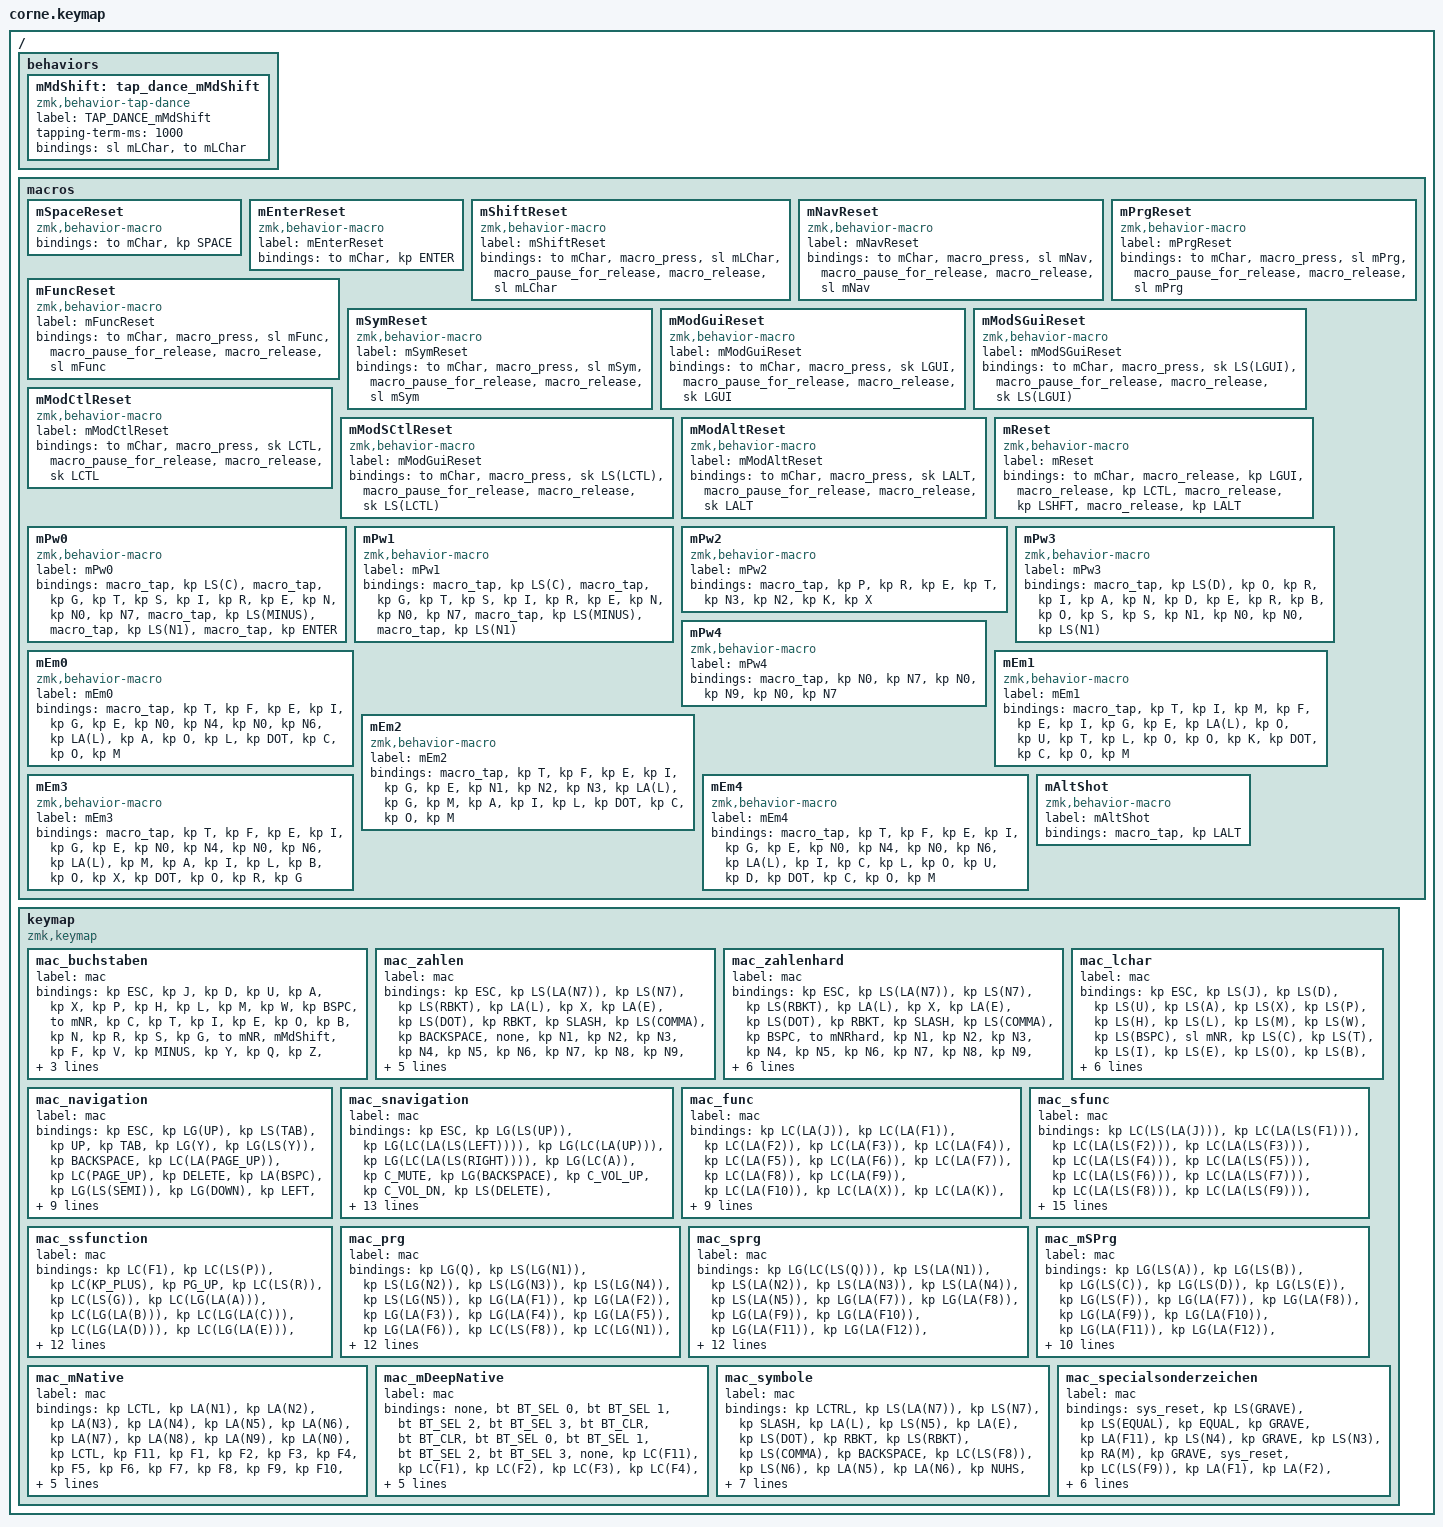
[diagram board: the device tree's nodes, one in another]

#include <behaviors.dtsi>
#include <dt-bindings/zmk/keys.h>
#include <dt-bindings/zmk/bt.h>


// ZMK Big



// ------- MAC -------------------

#define mChar 0
#define mNR 1
#define mNRhard 2
#define mLChar 3

#define mNav 4
#define mSNav 5

#define mFunc 6
#define mDFunc 7
#define mSFunc 8

#define mPrg 9
#define mDPrg 10
#define mSPrg 11

#define mNative 12
#define mDeepNative 13

#define mSym 14
#define mSSym 15





/ {

    behaviors 
	{

		//Tab Dance Shift
		mMdShift: tap_dance_mMdShift 
		{
            compatible = "zmk,behavior-tap-dance";
            label = "TAP_DANCE_mMdShift";
            #binding-cells = <0>;
            tapping-term-ms = <1000>;
            bindings = <&sl mLChar>, <&to mLChar>;
        };
    };

	


	macros 
	{

		//Reset Keys
        mSpaceReset: mSpaceReset 
		{
            compatible = "zmk,behavior-macro";
            #binding-cells = <0>;
            bindings
                = <&to mChar>
                , <&kp SPACE>
                ;
    	};
		mEnterReset: mEnterReset 
		{
            label = "mEnterReset";
            compatible = "zmk,behavior-macro";
            #binding-cells = <0>;
            bindings
                = <&to mChar>
                , <&kp ENTER>
                ;
    	};
		mShiftReset: mShiftReset
		{
            label = "mShiftReset";
            compatible = "zmk,behavior-macro";
            #binding-cells = <0>;
            bindings
                = <&to mChar>
                , <&macro_press &sl mLChar>
    			, <&macro_pause_for_release>
				, <&macro_release &sl mLChar>
                ;
    	};



		// Reset Stickys


				
		mNavReset: mNavReset 
		{
            label = "mNavReset";
            compatible = "zmk,behavior-macro";
            #binding-cells = <0>;
            bindings
                = <&to mChar>
                , <&macro_press &sl mNav>
    			, <&macro_pause_for_release>
				, <&macro_release &sl mNav>
                ;
    	};

		mPrgReset: mPrgReset 
		{
            label = "mPrgReset";
            compatible = "zmk,behavior-macro";
            #binding-cells = <0>;
            bindings
                = <&to mChar>
                , <&macro_press &sl mPrg>
    			, <&macro_pause_for_release>
				, <&macro_release &sl mPrg>
                ;
    	};

		mFuncReset: mFuncReset
		{
            label = "mFuncReset";
            compatible = "zmk,behavior-macro";
            #binding-cells = <0>;
            bindings
                = <&to mChar>
                , <&macro_press &sl mFunc>
    			, <&macro_pause_for_release>
				, <&macro_release &sl mFunc>
                ;
    	};

		mSymReset: mSymReset
		{
            label = "mSymReset";
            compatible = "zmk,behavior-macro";
            #binding-cells = <0>;
            bindings
                = <&to mChar>
                , <&macro_press &sl mSym>
    			, <&macro_pause_for_release>
				, <&macro_release &sl mSym>
                ;
    	};






		// Special Layer Reset

		mModGuiReset: mModGuiReset
		{
            label = "mModGuiReset";
            compatible = "zmk,behavior-macro";
            #binding-cells = <0>;
            bindings
                = <&to mChar>
                , <&macro_press &sk LGUI>
    			, <&macro_pause_for_release>
				, <&macro_release &sk LGUI>
                ;
    	};

		mModSGuiReset: mModSGuiReset
		{
            label = "mModSGuiReset";
            compatible = "zmk,behavior-macro";
            #binding-cells = <0>;
            bindings
                = <&to mChar>
                , <&macro_press &sk LS(LGUI)>
    			, <&macro_pause_for_release>
				, <&macro_release &sk LS(LGUI)>
                ;
    	};

		mModCtlReset: mModCtlReset
		{
            label = "mModCtlReset";
            compatible = "zmk,behavior-macro";
            #binding-cells = <0>;
            bindings
                = <&to mChar>
                , <&macro_press &sk LCTL>
    			, <&macro_pause_for_release>
				, <&macro_release &sk LCTL>
                ;
    	};

		mModSCtlReset: mModSCtlReset
		{
            label = "mModGuiReset";
            compatible = "zmk,behavior-macro";
            #binding-cells = <0>;
            bindings
                = <&to mChar>
                , <&macro_press &sk LS(LCTL)>
    			, <&macro_pause_for_release>
				, <&macro_release &sk LS(LCTL)>
                ;
    	};

		mModAltReset: mModAltReset
		{
            label = "mModAltReset";
            compatible = "zmk,behavior-macro";
            #binding-cells = <0>;
            bindings
                = <&to mChar>
                , <&macro_press &sk LALT>
    			, <&macro_pause_for_release>
				, <&macro_release &sk LALT>
                ;
    	};






		// Reset 

		mReset: mReset {
            label = "mReset";
            compatible = "zmk,behavior-macro";
            #binding-cells = <0>;
            bindings
				= <&to mChar>
				, <&macro_release  &kp LGUI>
				, <&macro_release  &kp LCTL>
				, <&macro_release  &kp LSHFT>
				, <&macro_release  &kp LALT>
                ; 
    	};
		






		// Pass Wort Macros

		mPw0: mPw0 {
            label = "mPw0";
            compatible = "zmk,behavior-macro";
            #binding-cells = <0>;
            bindings
				= < &macro_tap &kp LS(C)>
				, < &macro_tap &kp G &kp T &kp S &kp I &kp R &kp E &kp N &kp N0 &kp N7 >
				, < &macro_tap &kp LS(MINUS)>
				, < &macro_tap &kp LS(N1)>
				, < &macro_tap &kp ENTER>
                ; 
    	};
		
		mPw1: mPw1 {
            label = "mPw1";
            compatible = "zmk,behavior-macro";
            #binding-cells = <0>;
            bindings
				= < &macro_tap &kp LS(C)>
				, < &macro_tap &kp G &kp T &kp S &kp I &kp R &kp E &kp N &kp N0 &kp N7 >
				, < &macro_tap &kp LS(MINUS)>
				, < &macro_tap &kp LS(N1)>
                ; 
    	};


		mPw2: mPw2 {
            label = "mPw2";
            compatible = "zmk,behavior-macro";
            #binding-cells = <0>;
            bindings
				= <&macro_tap &kp P &kp R &kp E &kp T &kp N3 &kp N2 &kp K &kp X >
                ; 
    	};


		mPw3: mPw3 {
            label = "mPw3";
            compatible = "zmk,behavior-macro";
            #binding-cells = <0>;
            bindings
				= <&macro_tap &kp LS(D) &kp O &kp R &kp I &kp A &kp N &kp D &kp E &kp R &kp B &kp O &kp S &kp S &kp N1 &kp N0 &kp N0 &kp LS(N1) >
                ; 
    	};

		mPw4: mPw4 {
            label = "mPw4";
            compatible = "zmk,behavior-macro";
            #binding-cells = <0>;
            bindings
				= <&macro_tap &kp N0  &kp N7  &kp N0  &kp N9  &kp N0  &kp N7>
                ; 
    	};

		

		// Email

		mEm0: mEm0 {
            label = "mEm0";
            compatible = "zmk,behavior-macro";
            #binding-cells = <0>;
            bindings
				= < &macro_tap &kp T &kp F &kp E &kp I &kp G &kp E &kp N0 &kp N4 &kp N0  &kp N6  &kp LA(L)  &kp A  &kp O  &kp L  &kp DOT  &kp C  &kp O  &kp M>
                ; 
    	};

		mEm1: mEm1 {
            label = "mEm1";
            compatible = "zmk,behavior-macro";
            #binding-cells = <0>;
            bindings
				= < &macro_tap &kp T &kp I &kp M &kp F &kp E &kp I &kp G &kp E &kp LA(L)  &kp O  &kp U  &kp T  &kp L  &kp O &kp O &kp K  &kp DOT  &kp C  &kp O  &kp M>
                ; 
    	};

		mEm2: mEm2 {
            label = "mEm2";
            compatible = "zmk,behavior-macro";
            #binding-cells = <0>;
            bindings
				= < &macro_tap &kp T &kp F &kp E &kp I &kp G &kp E &kp N1 &kp N2  &kp N3 &kp LA(L)  &kp G  &kp M  &kp A  &kp I  &kp L  &kp DOT  &kp C  &kp O  &kp M>
                ; 
    	};

		mEm3: mEm3 {
            label = "mEm3";
            compatible = "zmk,behavior-macro";
            #binding-cells = <0>;
            bindings
				= < &macro_tap &kp T &kp F &kp E &kp I &kp G &kp E &kp N0 &kp N4 &kp N0  &kp N6  &kp LA(L)  &kp M  &kp A  &kp I  &kp L  &kp B  &kp O  &kp X  &kp DOT  &kp O  &kp R  &kp G>
                ; 
    	};

		mEm4: mEm4 {
            label = "mEm4";
            compatible = "zmk,behavior-macro";
            #binding-cells = <0>;
            bindings
				= < &macro_tap &kp T &kp F &kp E &kp I &kp G &kp E &kp N0 &kp N4 &kp N0  &kp N6  &kp LA(L)  &kp I  &kp C  &kp L  &kp O  &kp U  &kp D  &kp DOT  &kp C  &kp O  &kp M>
                ; 
    	};


		// Email

		mAltShot: mAltShot {
            label = "mAltShot";
            compatible = "zmk,behavior-macro";
            #binding-cells = <0>;
            bindings
				= < &macro_tap &kp LALT>
                ; 
    	};



	};





	keymap
	{	
		compatible = "zmk,keymap";


		// -----------------------------------------------------|
		// 							Buchstaben					|
		// -----------------------------------------------------|
	
		mac_buchstaben
		{
			label = "mac";

			bindings = <

				// ----------------------------------------

				&kp ESC
				&kp J 
				&kp D	 
				&kp U
				&kp A
				&kp X

				&kp P
				&kp H
				&kp L
				&kp M
				&kp W
				&kp BSPC

				// ----------------------------------------
	
				&to mNR
				&kp C
				&kp T
				&kp I
				&kp E
				&kp O

				&kp B
				&kp N
				&kp R
				&kp S
				&kp G
				&to mNR

				// ----------------------------------------
	
				&mMdShift
				&kp F
				&kp V
				&kp MINUS
				&kp Y
				&kp Q

				&kp Z
				&kp SEMI
				&kp LBKT
				&kp SQT
				&kp K
				&mMdShift

				// ----------------------------------------

				&sl mSym
				&kp SPACE
				&sl mFunc
				&sl mPrg 
				&sl mNav
				&sl mSym

				// ----------------------------------------
			>;
		};



		// -----------------------------------------------------|
		//						Zahlen 							|
		// -----------------------------------------------------|

		mac_zahlen
		{
			label = "mac";

			bindings = <

				// ----------------------------------------

				&kp ESC
				&kp LS(LA(N7))			// backlslash
				&kp LS(N7)				// /
				&kp LS(RBKT)			// *
				&kp LA(L)				// @
				&kp X
				
				&kp LA(E)				// €
				&kp LS(DOT)				// :
				&kp RBKT  				// +
				&kp SLASH 				// -
				&kp LS(COMMA)			// ;
				&kp BACKSPACE

				// ----------------------------------------

				&none
				&kp N1				
				&kp N2 
				&kp N3				
				&kp N4					
				&kp N5		

				&kp N6				
				&kp N7				
				&kp N8			
				&kp N9				
				&kp N0				
				&none

				// ----------------------------------------

				&mMdShift
				&kp LS(NUHS)			// '
				&kp NUBS				// Spitze
				&kp LS(NUBS)			// Spitze 
				&kp LS(N2)				// "
				&kp LS(SLASH)			// _

				&kp LS(N0)				// =
				&kp DOT					// .
				&kp COMMA				// ,
				&kp LA(N)				// ~
				&kp LA(N7)				// grader strich
				&mMdShift

				// ----------------------------------------
		
				&sl mSym
				&mSpaceReset 
				&mFuncReset
				&mPrgReset
				&mNavReset
				&sl mSym
			>;		
		};

		
		

		// -----------------------------------------------------|
		// 				 Zahlen Hard Lock						
		// -----------------------------------------------------|

		mac_zahlenhard
		{
			label = "mac";

			bindings = <

				// ----------------------------------------

				&kp ESC
				&kp LS(LA(N7))			// backlslash
				&kp LS(N7)				// /
				&kp LS(RBKT)			// *
				&kp LA(L)				// @
				&kp X
				
				&kp LA(E)				// €
				&kp LS(DOT)				// :
				&kp RBKT  				// +
				&kp SLASH 				// -
				&kp LS(COMMA)			// ;
				&kp BSPC

				// ----------------------------------------

				&to mNRhard
				&kp N1				
				&kp N2				
				&kp N3				
				&kp N4					
				&kp N5		

				&kp N6				
				&kp N7				
				&kp N8				
				&kp N9				
				&kp N0				
				&to mNRhard

				// ----------------------------------------

				&mMdShift
				&kp LS(NUHS)			// '
				&kp NUBS				// Spitze
				&kp LS(NUBS)			// Spitze 
				&kp LS(N2)				// "
				&kp LS(SLASH)			// _

				&kp LS(N0)				// =
				&kp DOT					// .
				&kp COMMA				// ,
				&kp LA(N)				// ~
				&kp LA(N7)				// grader strich
				&mMdShift

				// ----------------------------------------
		
				&sl mSym
				&kp SPACE
				&sl mFunc
				&sl mPrg
				&sl mNav
				&sl mSym
			>;		
		};




		// -----------------------------------------------------|
		// 							Buchstaben Lock				|
		// -----------------------------------------------------|
	
		mac_lchar
		{
			label = "mac";

			bindings = <

				// ----------------------------------------

				&kp ESC
				&kp LS(J) 
				&kp LS(D)	 
				&kp LS(U)
				&kp LS(A)
				&kp LS(X)

				&kp LS(P)
				&kp LS(H)
				&kp LS(L)
				&kp LS(M)
				&kp LS(W)
				&kp LS(BSPC) 

				// ----------------------------------------
	
				&sl mNR
				&kp LS(C)
				&kp LS(T)
				&kp LS(I)
				&kp LS(E)
				&kp LS(O)
			
				&kp LS(B)
				&kp LS(N)
				&kp LS(R)
				&kp LS(S)
				&kp LS(G)
				&sl mNR

				// ----------------------------------------

				&mMdShift
				&kp LS(F)
				&kp LS(V)
				&kp LS(MINUS)
				&kp LS(Y)
				&kp LS(Q)

				&kp LS(Z)
				&kp LS(SEMI)
				&kp LS(LBKT)
				&kp LS(SQT)
				&kp LS(K)
				&mMdShift

				// ----------------------------------------

				&sl mSym
				&mSpaceReset 
				&mFuncReset
				&mPrgReset
				&sl mNav
				&sl mSym

				// ----------------------------------------		
			>;
		};






		// -----------------------------------------------------|
		// 						Navigation						|
		// -----------------------------------------------------|

		mac_navigation
		{		
			label = "mac";

			bindings = <

				// ----------------------------------------

				&kp ESC
				&kp LG(UP)					
				&kp LS(TAB)
				&kp UP						
				&kp TAB
				&kp LG(Y)

				&kp LG(LS(Y))
				&kp BACKSPACE
				&kp LC(LA(PAGE_UP))
				&kp LC(PAGE_UP)
				&kp DELETE
				&kp LA(BSPC)					


				// ----------------------------------------

				&kp LG(LS(SEMI))
				&kp LG(DOWN)				// @End Sprung
				&kp LEFT 					// @Left
				&kp DOWN					// @Down
				&kp RIGHT 					// @Right
				&kp ENTER					
				
				&kp LC(LS(F10))				
				&kp LSHFT
				&kp LC(LA(PAGE_DOWN))
				&kp LC(PAGE_DOWN)
				&kp LCTL
				&kp LG(ENTER)
				
				// ----------------------------------------

				&kp LG(SEMI)
				&kp LG(LEFT)				// @Home 
				&kp LA(LEFT)				// @Wort Sprung
				&kp LA(RIGHT)				// @Wort Sprung
				&kp LG(RIGHT)				// @End  
				&kp LG(SQT)

				&kp LC(LA(LG(ENTER)))		// Altshot bzw Shortcat
				&kp LC(LA(F11))				
				&kp LC(LS(TAB))
				&kp LC(TAB)
				&kp LC(LA(F12))				
				&kp LALT

				// ----------------------------------------

				&sl mSym
				&to mNRhard
				&sl mFunc
				&sl mPrg
				&sl mSNav
				&sl mSym

				// ----------------------------------------							
			>;
		};


		// -----------------------------------------------------|
		//					Deep Navigation						|
		// -----------------------------------------------------|

		mac_snavigation
		{		
			label = "mac";

			bindings = <

				// ----------------------------------------

				&kp ESC 
				&kp LG(LS(UP))					
				&kp LG(LC(LA(LS(LEFT))))
				&kp LG(LC(LA(UP)))
				&kp LG(LC(LA(LS(RIGHT))))
				&kp LG(LC(A))		

				&kp C_MUTE
				&kp LG(BACKSPACE)
				&kp C_VOL_UP
				&kp C_VOL_DN
				&kp LS(DELETE)
				&kp LC(LS(BACKSPACE))

				// ----------------------------------------
		
				&kp LG(LS(SEMI))
				&kp LG(LS(DOWN))				// @End Sprung
				&kp LG(LC(LA(LEFT)))
				&kp LG(LC(LA(DOWN)))
				&kp LG(LC(LA(RIGHT)))
				&kp LG(LS(SQT))	

				&kp C_PLAY			
				&kp C_BRI_INC
				&kp C_PREV
				&kp C_NEXT
				&kp C_BRI_DEC
				&kp LCTL

				// ----------------------------------------

				&kp LG(LA(SEMI))
				&kp LG(LS(LEFT))				// @Home 
				&kp LA(LS(LEFT))				// @Wort Sprung
				&kp LA(LS(RIGHT))				// @Wort Sprung
				&kp LG(LS(RIGHT))				// @End  
				&kp LG(LA(SQT))
				
				&kp LG(LS(SEMI))
				&kp LC(LA(LS(F11)))
				&kp LC(LA(LEFT))
				&kp LC(LA(RIGHT))
				&kp LC(LA(LS(F12)))			
				&kp LG(LS(SQT))

				// ----------------------------------------
		
				&sl mSym
				&kp SPACE				
				&sl mFunc
				&sl mPrg
				&sl mNav
				&sl mSym

				// ----------------------------------------							
			>;
		};




				











		// -----------------------------------------------------|
		// Funktionen											|
		// -----------------------------------------------------|

		mac_func
		{
			label = "mac";

			bindings = <

				// ----------------------------------------
	
				&kp LC(LA(J))	
				&kp LC(LA(F1))	
				&kp LC(LA(F2))	
				&kp LC(LA(F3))	
				&kp LC(LA(F4))	
				&kp LC(LA(F5))	

				&kp LC(LA(F6))	
				&kp LC(LA(F7))	
				&kp LC(LA(F8))	
				&kp LC(LA(F9))	
				&kp LC(LA(F10))	
				&kp LC(LA(X))	
				
				// ----------------------------------------

				&kp LC(LA(K))	
				&kp LG(A)
				&kp LC(LA(A))	
				&kp LC(LA(B))	
				&kp LG(C)			
				&kp LG(X)

				&kp LC(LA(O))	
				&kp LG(V)
				&kp LC(LA(T))	
				&kp LC(LA(U))	
				&kp LC(LA(V))	
				&kp LC(LA(W))	

				// ----------------------------------------

				&kp LC(LA(I))	
				&kp LC(LA(S))
				&kp LC(LA(N))				
				&kp LC(LA(M))
				&kp LC(LA(R))	
				&kp LC(LA(G))

				&kp LC(LA(H))
				&kp LC(LA(F))	
				&kp LC(LA(D))	
				&kp LC(LA(C))	
				&kp LC(LA(E))
				&kp LC(LA(Y))	
				
				// ----------------------------------------

				&sl mSym
				&sl mSFunc
				&sl mDFunc					
				&sl mNative
				&mModCtlReset
				&sl mSym

				// ----------------------------------------
			>;
		};



		// -----------------------------------------------------|
		// 						Spezial Funktionen				|
		// -----------------------------------------------------|

		mac_sfunc
		{
			label = "mac";

			bindings = <

			// ----------------------------------------
	
				&kp LC(LS(LA(J)))	
				&kp LC(LA(LS(F1)))	
				&kp LC(LA(LS(F2)))	
				&kp LC(LA(LS(F3)))	
				&kp LC(LA(LS(F4)))
				&kp LC(LA(LS(F5)))

				&kp LC(LA(LS(F6)))	
				&kp LC(LA(LS(F7)))	
				&kp LC(LA(LS(F8)))	
				&kp LC(LA(LS(F9)))
				&kp LC(LA(LS(F10)))
				&kp LC(LS(LA(X)))	
				
				// ----------------------------------------

				&kp LC(LS(LA(K)))	
				&kp LC(LS(LA(P)))	
				&kp LC(LS(LA(A)))	
				&kp LC(LS(LA(B)))
				&kp LC(LS(LA(C)))			
				&kp LC(LS(LA(X)))	

				&kp LC(LS(LA(O)))
				&kp LC(LS(LA(V)))	
				&kp LC(LS(LA(T)))	
				&kp LC(LS(LA(U)))	
				&kp LC(LS(LA(L)))
				&kp LC(LS(LA(W)))	
					

				// ----------------------------------------

				&kp LC(LS(LA(I)))	
				&kp LC(LS(LA(S)))	
				&kp LC(LS(LA(N)))
				&kp LC(LS(LA(M)))
				&kp LC(LS(LA(R)))	
				&kp LC(LS(LA(G)))	

				&kp LC(LA(LS(H)))	
				&kp LC(LS(LA(F)))
				&kp LC(LS(LA(D)))
				&kp LC(LS(LA(C)))
				&kp LC(LS(LA(E)))
				&kp LC(LS(LA(Y)))	
				
				// ----------------------------------------

				&sl mSym	
				&mModGuiReset
				&sl mDFunc
				&sl mDeepNative
				&mModSCtlReset
				&sl mSym

				// ----------------------------------------       
			>;
		};







		// -----------------------------------------------------|
		// 				Super Special Function					|
		// -----------------------------------------------------|

		mac_ssfunction
		{
			label = "mac";

			bindings = <

			// ----------------------------------------

				&kp LC(F1)
				&kp LC(LS(P))
				&kp LC(KP_PLUS)
				&kp PG_UP
				&kp LC(LS(R))
				&kp LC(LS(G))

				&kp LC(LG(LA(A)))
				&kp LC(LG(LA(B)))
				&kp LC(LG(LA(C)))
				&kp LC(LG(LA(D)))
				&kp LC(LG(LA(E)))
				&kp LC(LG(LA(F)))

				// ----------------------------------------
		
				&kp LA(TAB)
				&kp LC(P)
				&kp LC(KP_MINUS)
				&kp PG_DN
				&kp LC(R)
				&kp LC(G)

				&kp LC(LG(LA(G)))
				&kp LC(LG(LA(I)))
				&kp LC(LG(LA(J)))
				&kp LC(LG(LA(K)))
				&kp LC(LG(LA(L)))
				&kp LC(LG(LA(M)))

				// ----------------------------------------

				&kp LC(LS(S))
				&kp LC(S)
				&kp LC(Y)
				&kp LC(LS(Y))
				&kp LC(LG(LA(W)))
				&kp LG(LS(S))

				&kp LC(LG(LA(N)))
				&kp LC(LG(LA(O)))
				&kp LC(LG(LA(P)))
				&kp LC(LG(LA(Q)))
				&kp LC(LG(LA(R)))
				&kp LC(LG(LA(S)))

				// ----------------------------------------
		
				&sl mSym	
				&kp SPACE
				&sl mFunc				
				&sl mSPrg
				&mModAltReset
				&sl mSym

				// ----------------------------------------
				
			>;
		};


		












		// -----------------------------------------------------|
		//  				Programme							|
		// -----------------------------------------------------|

		mac_prg
		{
			label = "mac";

			bindings = <

				// ----------------------------------------

				&kp LG(Q)
				&kp LS(LG(N1))			// 21 			
				&kp LS(LG(N2))			// 22
				&kp LS(LG(N3))			// 23
				&kp LS(LG(N4))			// 24
				&kp LS(LG(N5))			// 25
	
				&kp LG(LA(F1))			// 26
				&kp LG(LA(F2))			// 26
				&kp LG(LA(F3))			// 26
				&kp LG(LA(F4))			// 26
				&kp LG(LA(F5))			// 26
				&kp LG(LA(F6))			// 26

				// ----------------------------------------

				&kp LC(LS(F8))				// prg wechsel
				&kp LC(LG(N1))			
				&kp LC(LG(N2))		
				&kp LC(LG(N3))			
				&kp LC(LG(N4))			
				&kp LC(LG(N5))			

				&kp LG(LC(LA(F1)))
				&kp LG(LC(LA(F2)))
				&kp LG(LC(LA(F3)))
				&kp LG(LC(LA(F4)))
				&kp LG(LC(LA(F5)))
				&kp LG(LC(LA(F6)))

				// ----------------------------------------

				&kp LC(LS(F9))					// Prg Wechsel	
				&kp LC(LG(N6))				
				&kp LC(LG(N7))				
				&kp LC(LG(N8))				
				&kp LC(LG(N9))				
				&kp LC(LG(N0))			

				&kp LG(LC(LA(F7)))
				&kp LG(LC(LA(F8)))
				&kp LG(LC(LA(F9)))
				&kp LG(LC(LA(F10)))
				&kp LG(LC(LA(F11)))
				&kp LG(LC(LA(F12)))
		
				// ----------------------------------------

				&sl mSym
				&kp LG(LC(LA(X)))		
				&sl mNative
				&sl mDPrg					// deep						
				&sl mSPrg					// special
				&sl mSym

				// ----------------------------------------

			>;
		};
		


		// -----------------------------------------------------|
		// 		Spezial Prgramme								|
		// -----------------------------------------------------|


		mac_sprg
		{

			label = "mac";

			bindings = <

				// ----------------------------------------

				&kp LG(LC(LS(Q)))
				&kp LS(LA(N1))			// 21 			
				&kp LS(LA(N2))			// 22
				&kp LS(LA(N3))			// 23
				&kp LS(LA(N4))			// 24
				&kp LS(LA(N5))			// 25

				&kp LG(LA(F7))			// 
				&kp LG(LA(F8))			// 
				&kp LG(LA(F9))			// 
				&kp LG(LA(F10))			// 
				&kp LG(LA(F11))			// 
				&kp LG(LA(F12))			// 
				
				// ----------------------------------------

				&kp LG(LC(LS(M)))
				&kp LG(LC(LA(N1)))
				&kp LG(LC(LA(N2)))
				&kp LG(LC(LA(N3)))
				&kp LG(LC(LA(N4)))
				&kp LG(LC(LA(N5)))

				&kp LG(LS(F1))
				&kp LG(LS(F2))
				&kp LG(LS(F3))
				&kp LG(LS(F4))
				&kp LG(LS(F5))
				&kp LG(LS(F6))

				// ----------------------------------------

				&kp LG(LC(LS(N)))
				&kp LG(LC(LA(N6)))
				&kp LG(LC(LA(N7)))
				&kp LG(LC(LA(N8)))
				&kp LG(LC(LA(N9)))
				&kp LG(LC(LA(N0)))

				&kp LG(LS(F7))
				&kp LG(LS(F8))
				&kp LG(LS(F9))
				&kp LG(LS(F10))
				&kp LG(LS(F11))
				&kp LG(LS(F12))

				// ----------------------------------------

				&sl mSym
				&kp LG(LC(LA(Y)))			
				&sl mDeepNative
				&sl mDPrg
				&sl mSPrg				
				&sl mSym		

				// ----------------------------------------

			>;
		};





		// -----------------------------------------------------|
		// 		Super Special Program
		// -----------------------------------------------------|

		mac_mSPrg
		{
			label = "mac";

			bindings = <

				// ----------------------------------------

				&kp LG(LS(A))
				&kp LG(LS(B))
				&kp LG(LS(C))
				&kp LG(LS(D))
				&kp LG(LS(E))
				&kp LG(LS(F))

				&kp LG(LA(F7))			// 
				&kp LG(LA(F8))			// 
				&kp LG(LA(F9))			// 
				&kp LG(LA(F10))			// 
				&kp LG(LA(F11))			// 
				&kp LG(LA(F12))			// 


				// ----------------------------------------
		
				&kp LG(LS(G))
				&kp LG(LS(I))
				&kp LG(LS(J))
				&kp LG(LS(K))
				&kp LG(LS(L))
				&kp LG(LS(M))

				&kp LG(LS(F1))
				&kp LG(LS(F2))
				&kp LG(LS(F3))
				&kp LG(LS(F4))
				&kp LG(LS(F5))
				&kp LG(LS(F6))


				// ----------------------------------------

				&kp LG(LS(N))
				&kp LG(LS(O))
				&kp LG(LS(P))
				&kp LG(LS(Q))
				&kp LG(LS(R))
				&kp LG(LS(S))

				&kp LG(LS(F7))
				&kp LG(LS(F8))
				&kp LG(LS(F9))
				&kp LG(LS(F10))
				&kp LG(LS(F11))
				&kp LG(LS(F12))

				// ----------------------------------------
		
				&sl mSym
				&kp LG(LC(LA(Z)))		
				&sl mFunc
				&sl mPrg				
				&sl mNav
				&sl mSym

				// ----------------------------------------

				
			>;
		};

		






		// -----------------------------------------------------|
		// 					Nativ 								|
		// -----------------------------------------------------|

		mac_mNative
		{
			label = "mac";

			bindings = <

			// ----------------------------------------

				&kp LCTL
				&kp LA(N1)
				&kp LA(N2)
				&kp LA(N3)
				&kp LA(N4)
				&kp LA(N5)

				&kp LA(N6)
				&kp LA(N7)
				&kp LA(N8)
				&kp LA(N9)
				&kp LA(N0)
				&kp LCTL

				// ----------------------------------------
		
				&kp F11
				&kp F1
				&kp F2
				&kp F3
				&kp F4
				&kp F5

				&kp F6
				&kp F7
				&kp F8
				&kp F9
				&kp F10
				&kp F12
		

				// ----------------------------------------

				&kp LSHFT
				&kp LC(N1)
				&kp LC(N2)
				&kp LC(N3)
				&kp LC(N4)
				&kp LC(N5)

				&kp LC(N6)
				&kp LC(N7)
				&kp LC(N8)
				&kp LC(N9)
				&kp LC(N0)
				&kp LSHFT

				// ----------------------------------------
		
				&sl mSym					
				&kp SPACE
				&sl mFunc				
				&sl mPrg				
				&sl mNav
				&sl mSym

				// ----------------------------------------
				
			>;
		};


		
		// -----------------------------------------------------|
		// 				deep Native
		// -----------------------------------------------------|

		mac_mDeepNative
		{
			label = "mac";

			bindings = <

				// ----------------------------------------

				&none
				&bt BT_SEL 0
				&bt BT_SEL 1
				&bt BT_SEL 2
				&bt BT_SEL 3
				&bt BT_CLR

				&bt BT_CLR
				&bt BT_SEL 0
				&bt BT_SEL 1
				&bt BT_SEL 2
				&bt BT_SEL 3
				&none


				// ----------------------------------------
		
				&kp LC(F11)
				&kp LC(F1)
				&kp LC(F2)
				&kp LC(F3)
				&kp LC(F4)
				&kp LC(F5)

				&kp LC(F6)
				&kp LC(F7)
				&kp LC(F8)
				&kp LC(F9)
				&kp LC(F10)
				&kp LC(F12)


				// ----------------------------------------

				&none
				&none
				&none
				&none
				&none
				&none				

				&none
				&none
				&none
				&none
				&none
				&none


				// ----------------------------------------
		
				&sl mSym					
				&kp SPACE
				&sl mFunc				
				&sl mPrg				
				&sl mNav
				&sl mSym

				// ----------------------------------------

				
			>;
		};













		// -----------------------------------------------------|
		// 						Symoble							|
		// -----------------------------------------------------|

		mac_symbole
		{
			label = "mac";

			bindings = <

				// ----------------------------------------
				
				&kp LCTRL
				&kp LS(LA(N7))			// backlslash
				&kp LS(N7)				// /
				&kp SLASH 				// -
				&kp LA(L)				// @
				&kp LS(N5)				// %
				
				&kp LA(E)				// €
				&kp LS(DOT)				// :
				&kp RBKT  				// +
				&kp LS(RBKT)			// *
				&kp LS(COMMA)			// ;
				&kp BACKSPACE

				// ----------------------------------------

				&kp LC(LS(F8))			// prg wechsel
				&kp LS(N6)				// &
				&kp LA(N5)				// Eckige
				&kp LA(N6)				// Eckige
				&kp NUHS				// #
				&kp LA(N8)				// Geschweift

				&kp LA(N9)				// Geschweift
				&kp LS(N1)				// !
				&kp LS(N8)				// Runde
				&kp LS(N9)				// Runde
				&kp LS(MINUS)			// ?
				&kp GRAVE				// ^ 

				// ----------------------------------------

				&kp LSHFT
				&kp LS(NUHS)			// '
				&kp NUBS				// Spitze
				&kp LS(NUBS)			// Spitze 
				&kp LS(N2)				// "
				&kp LS(SLASH)			// _

				&kp LS(N0)				// =
				&kp DOT					// .
				&kp COMMA				// ,
				&kp LA(N)				// ~
				&kp LA(N7)				// grader strich
				&kp LG(LC(SPACE))   	// @Sonderzeichen
		
		
				// ----------------------------------------

				&sl mSSym				
				&mReset
				&sl mFunc				
				&sl mPrg						
				&sl mNav
				&sl mSSym				

				// ----------------------------------------
			>;
		};


		// -----------------------------------------------------|
		// 						Special Symbole					|
		// -----------------------------------------------------|

		mac_specialsonderzeichen
		{
			label = "mac";

			bindings = <

				// ----------------------------------------
				
				&sys_reset
				&kp LS(GRAVE)				// Grad
				&kp LS(EQUAL)
				&kp EQUAL
				&kp GRAVE
				&kp LA(F11)

				&kp LS(N4) 				// Dollar
				&kp GRAVE
				&kp LS(N3) 				// Para
				&kp RA(M)				// my
				&kp GRAVE
				&sys_reset

				// ----------------------------------------

				&kp LC(LS(F9))			// prg wechsel
				&kp LA(F1)
				&kp LA(F2)
				&kp LA(F3)
				&kp LA(F4)
				&kp LA(F5)

				&kp LA(F6)
				&kp LA(F7)
				&kp LA(F8)
				&kp LA(F9)
				&kp LA(F10)
				&kp GRAVE

				// ----------------------------------------

				&kp LGUI
				&mEm4
				&mEm3
				&mEm2
				&mEm1
				&mEm0

				&mPw0
				&mPw1
				&mPw2
				&mPw3
				&mPw4
				&kp LG(LC(SPACE))   	// @Sonderzeichen

				// ----------------------------------------

				&sl mSym					
				&mReset
				&sl mFunc				
				&sl mPrg				
				&sl mNav
				&sl mSym

				// ----------------------------------------
			>;
		};	
		



	};
};

